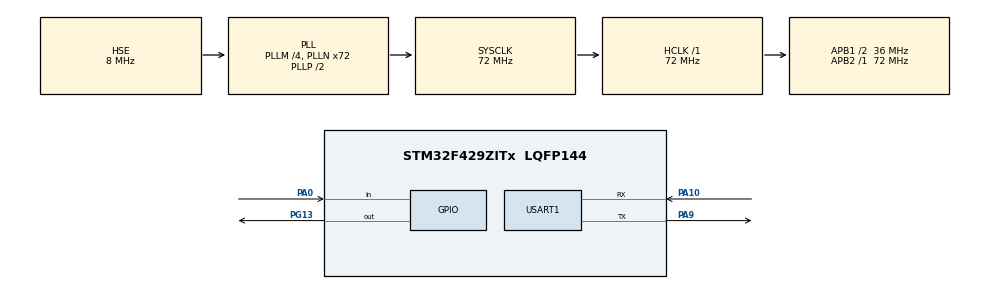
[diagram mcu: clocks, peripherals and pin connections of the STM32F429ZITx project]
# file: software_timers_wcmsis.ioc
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FREERTOS.Tasks01=uartTask,0,128,UartTask,Default,NULL,Dynamic,NULL,NULL;ledTask,0,128,LedTask,Default,NULL,Dynamic,NULL,NULL
FREERTOS.Timers01=periodictimer,PTCallback,osTimerPeriodic,Default,NULL,Dynamic,NULL;onceTimer,OTCallback,osTimerOnce,Default,NULL,Dynamic,NULL
FREERTOS.configTIMER_TASK_PRIORITY=6
FREERTOS.configUSE_TIMERS=1
Mcu.Family=STM32F4
Mcu.Name=STM32F429ZITx
Mcu.Package=LQFP144
NVIC.PriorityGroup=NVIC_PRIORITYGROUP_4
NVIC.TIM1_UP_TIM10_IRQn=true\:15\:0\:false\:false\:true\:false\:false\:true\:true
NVIC.TimeBase=TIM1_UP_TIM10_IRQn
NVIC.TimeBaseIP=TIM1
PA0/WKUP.GPIO_PuPd=GPIO_PULLDOWN
PA0/WKUP.Signal=GPIO_Input
PA10.Mode=Asynchronous
PA10.Signal=USART1_RX
PA13.Mode=Serial_Wire
PA13.Signal=SYS_JTMS-SWDIO
PA14.Mode=Serial_Wire
PA14.Signal=SYS_JTCK-SWCLK
PA9.Mode=Asynchronous
PA9.Signal=USART1_TX
PG13.GPIO_PuPd=GPIO_PULLDOWN
PG13.Signal=GPIO_Output
PH0/OSC_IN.Mode=HSE-External-Oscillator
PH0/OSC_IN.Signal=RCC_OSC_IN
PH1/OSC_OUT.Mode=HSE-External-Oscillator
PH1/OSC_OUT.Signal=RCC_OSC_OUT
ProjectManager.HeapSize=0x200
ProjectManager.StackSize=0x400
ProjectManager.TargetToolchain=STM32CubeIDE
RCC.48MHZClocksFreq_Value=48000000
RCC.AHBFreq_Value=72000000
RCC.APB1CLKDivider=RCC_HCLK_DIV2
RCC.APB1Freq_Value=36000000
RCC.APB1TimFreq_Value=72000000
RCC.APB2Freq_Value=72000000
RCC.APB2TimFreq_Value=72000000
RCC.CortexFreq_Value=72000000
RCC.HCLKFreq_Value=72000000
RCC.HSE_VALUE=8000000
RCC.HSI_VALUE=16000000
RCC.LSE_VALUE=32768
RCC.PLLM=4
RCC.PLLN=72
RCC.PLLQ=3
RCC.PLLSAIN=50
RCC.PLLSourceVirtual=RCC_PLLSOURCE_HSE
RCC.SYSCLKFreq_VALUE=72000000
RCC.SYSCLKSource=RCC_SYSCLKSOURCE_PLLCLK
RCC.VCOOutputFreq_Value=144000000
USART1.VirtualMode=VM_ASYNC
VP_FREERTOS_VS_CMSIS_V1.Mode=CMSIS_V1
VP_SYS_VS_tim1.Mode=TIM1
board=STM32F429I-DISC1

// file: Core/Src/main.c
/* USER CODE BEGIN Header */
/**
  ******************************************************************************
  * @file           : main.c
  * @brief          : Main program body
  ******************************************************************************
  * @attention
  *
  * Copyright (c) 2025 STMicroelectronics.
  * All rights reserved.
  *
  * This software is licensed under terms that can be found in the LICENSE file
  * in the root directory of this software component.
  * If no LICENSE file comes with this software, it is provided AS-IS.
  *
  ******************************************************************************
  */
/* USER CODE END Header */
#include "main.h"
#include "cmsis_os.h"

UART_HandleTypeDef huart1;

osThreadId uartTaskHandle;
osThreadId ledTaskHandle;
osTimerId periodictimerHandle;
osTimerId onceTimerHandle;

void SystemClock_Config(void);
static void MX_GPIO_Init(void);
static void MX_USART1_UART_Init(void);
void UartTask(void const * argument);
void LedTask(void const * argument);
void PTCallback(void const * argument);
void OTCallback(void const * argument);

int main(void)
{

  /* MCU Configuration--------------------------------------------------------*/

  /* Reset of all peripherals, Initializes the Flash interface and the Systick. */
  HAL_Init();

  /* Configure the system clock */
  SystemClock_Config();

  /* Initialize all configured peripherals */
  MX_GPIO_Init();
  MX_USART1_UART_Init();

  /* Create the timer(s) */
  /* definition and creation of periodictimer */
  osTimerDef(periodictimer, PTCallback);
  periodictimerHandle = osTimerCreate(osTimer(periodictimer), osTimerPeriodic, NULL);

  /* definition and creation of onceTimer */
  osTimerDef(onceTimer, OTCallback);
  onceTimerHandle = osTimerCreate(osTimer(onceTimer), osTimerOnce, NULL);

  /* Create the thread(s) */
  /* definition and creation of uartTask */
  osThreadDef(uartTask, UartTask, osPriorityNormal, 0, 128);
  uartTaskHandle = osThreadCreate(osThread(uartTask), NULL);

  /* definition and creation of ledTask */
  osThreadDef(ledTask, LedTask, osPriorityNormal, 0, 128);
  ledTaskHandle = osThreadCreate(osThread(ledTask), NULL);

  /* Start scheduler */
  osKernelStart();

  /* We should never get here as control is now taken by the scheduler */

  /* Infinite loop */
  while (1)
  {

  }
}

void SystemClock_Config(void)
{
  RCC_OscInitTypeDef RCC_OscInitStruct = {0};
  RCC_ClkInitTypeDef RCC_ClkInitStruct = {0};

  /** Configure the main internal regulator output voltage
  */
  __HAL_RCC_PWR_CLK_ENABLE();
  __HAL_PWR_VOLTAGESCALING_CONFIG(PWR_REGULATOR_VOLTAGE_SCALE3);

  /** Initializes the RCC Oscillators according to the specified parameters
  * in the RCC_OscInitTypeDef structure.
  */
  RCC_OscInitStruct.OscillatorType = RCC_OSCILLATORTYPE_HSE;
  RCC_OscInitStruct.HSEState = RCC_HSE_ON;
  RCC_OscInitStruct.PLL.PLLState = RCC_PLL_ON;
  RCC_OscInitStruct.PLL.PLLSource = RCC_PLLSOURCE_HSE;
  RCC_OscInitStruct.PLL.PLLM = 4;
  RCC_OscInitStruct.PLL.PLLN = 72;
  RCC_OscInitStruct.PLL.PLLP = RCC_PLLP_DIV2;
  RCC_OscInitStruct.PLL.PLLQ = 3;
  if (HAL_RCC_OscConfig(&RCC_OscInitStruct) != HAL_OK)
  {
    Error_Handler();
  }

  /** Initializes the CPU, AHB and APB buses clocks
  */
  RCC_ClkInitStruct.ClockType = RCC_CLOCKTYPE_HCLK|RCC_CLOCKTYPE_SYSCLK
                              |RCC_CLOCKTYPE_PCLK1|RCC_CLOCKTYPE_PCLK2;
  RCC_ClkInitStruct.SYSCLKSource = RCC_SYSCLKSOURCE_PLLCLK;
  RCC_ClkInitStruct.AHBCLKDivider = RCC_SYSCLK_DIV1;
  RCC_ClkInitStruct.APB1CLKDivider = RCC_HCLK_DIV2;
  RCC_ClkInitStruct.APB2CLKDivider = RCC_HCLK_DIV1;

  if (HAL_RCC_ClockConfig(&RCC_ClkInitStruct, FLASH_LATENCY_2) != HAL_OK)
  {
    Error_Handler();
  }
}

static void MX_USART1_UART_Init(void)
{

  huart1.Instance = USART1;
  huart1.Init.BaudRate = 115200;
  huart1.Init.WordLength = UART_WORDLENGTH_8B;
  huart1.Init.StopBits = UART_STOPBITS_1;
  huart1.Init.Parity = UART_PARITY_NONE;
  huart1.Init.Mode = UART_MODE_TX_RX;
  huart1.Init.HwFlowCtl = UART_HWCONTROL_NONE;
  huart1.Init.OverSampling = UART_OVERSAMPLING_16;
  if (HAL_UART_Init(&huart1) != HAL_OK)
  {
    Error_Handler();
  }

}

static void MX_GPIO_Init(void)
{
  GPIO_InitTypeDef GPIO_InitStruct = {0};

  /* GPIO Ports Clock Enable */
  __HAL_RCC_GPIOH_CLK_ENABLE();
  __HAL_RCC_GPIOA_CLK_ENABLE();
  __HAL_RCC_GPIOG_CLK_ENABLE();

  /*Configure GPIO pin Output Level */
  HAL_GPIO_WritePin(GPIOG, GPIO_PIN_13, GPIO_PIN_RESET);

  /*Configure GPIO pin : PA0 */
  GPIO_InitStruct.Pin = GPIO_PIN_0;
  GPIO_InitStruct.Mode = GPIO_MODE_INPUT;
  GPIO_InitStruct.Pull = GPIO_PULLDOWN;
  HAL_GPIO_Init(GPIOA, &GPIO_InitStruct);

  /*Configure GPIO pin : PG13 */
  GPIO_InitStruct.Pin = GPIO_PIN_13;
  GPIO_InitStruct.Mode = GPIO_MODE_OUTPUT_PP;
  GPIO_InitStruct.Pull = GPIO_PULLDOWN;
  GPIO_InitStruct.Speed = GPIO_SPEED_FREQ_LOW;
  HAL_GPIO_Init(GPIOG, &GPIO_InitStruct);

}

void UartTask(void const * argument)
{
  /* USER CODE BEGIN 5 */
	osTimerStart(periodictimerHandle, 1000);
  /* Infinite loop */
  for(;;)
  {
		HAL_UART_Transmit(&huart1, (uint8_t*) "Sending from UART TASK\n", 23, 100);
		osDelay(2000);
  }
  /* USER CODE END 5 */
}

void LedTask(void const * argument)
{
  /* USER CODE BEGIN LedTask */
  /* Infinite loop */
  for(;;)
  {
	  if(HAL_GPIO_ReadPin(GPIOA, GPIO_PIN_0))  //press the button
	  {
		  HAL_GPIO_WritePin(GPIOG, GPIO_PIN_13, GPIO_PIN_SET); //set the led
		  osTimerStart(onceTimerHandle, 4000);
	  }
    osDelay(20);
  }
  /* USER CODE END LedTask */
}

/* PTCallback function */
void PTCallback(void const * argument)
{
  /* USER CODE BEGIN PTCallback */
	HAL_UART_Transmit(&huart1, (uint8_t*) "Sending from PERIODIC TIMER\n", 28, 100);
  /* USER CODE END PTCallback */
}

/* OTCallback function */
void OTCallback(void const * argument)
{
  /* USER CODE BEGIN OTCallback */
	HAL_GPIO_WritePin(GPIOG, GPIO_PIN_13, GPIO_PIN_RESET);
  /* USER CODE END OTCallback */
}

void HAL_TIM_PeriodElapsedCallback(TIM_HandleTypeDef *htim)
{
  if (htim->Instance == TIM1) {
    HAL_IncTick();
  }
}

void Error_Handler(void)
{
  __disable_irq();
  while (1)
  {
  }
}
